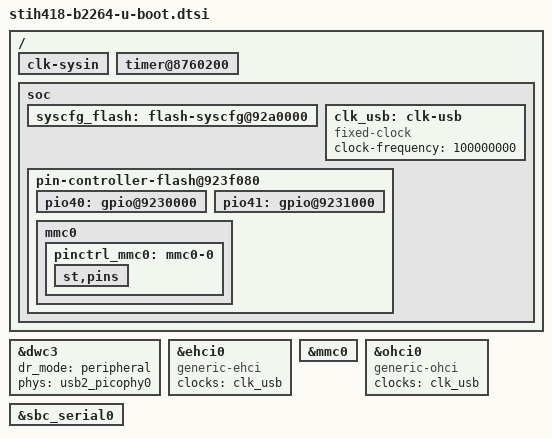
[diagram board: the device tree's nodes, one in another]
// SPDX-License-Identifier: GPL-2.0
/*
 * Author(s): Alain Volmat, <avolmat@me.com>
 *
 */

/ {
	clk-sysin {
		bootph-all;
	};

	timer@8760200 {
		bootph-all;
	};

	soc {
		bootph-all;
		syscfg_flash: flash-syscfg@92a0000 {
			bootph-all;
		};
		clk_usb: clk-usb {
			compatible = "fixed-clock";
			#clock-cells = <0>;
			clock-frequency = <100000000>;
		};
		pin-controller-flash@923f080 {
			bootph-all;
			pio40: gpio@9230000 {
				bootph-all;
			};
			pio41: gpio@9231000 {
				bootph-all;
			};
			mmc0 {
				bootph-all;
				pinctrl_mmc0: mmc0-0 {
					bootph-all;
					st,pins {
						bootph-all;
					};
				};
			};
		};
	};
};

&dwc3 {
	dr_mode	= "peripheral";
	phys = <&usb2_picophy0>;
};

&ehci0 {
	compatible = "generic-ehci";
	clocks = <&clk_usb>;
};

&mmc0 {
	/delete-property/ assigned-clocks;
	/delete-property/ assigned-clock-parents;
	/delete-property/ assigned-clock-rates;
	bootph-all;
};

&ohci0 {
	compatible = "generic-ohci";
	clocks = <&clk_usb>;
};

&sbc_serial0 {
	bootph-all;
};
